# UART3 register map
Vendor: Texas Instruments
Peripheral module from a debugger description file (folder omap4460).
Registers are 32-bit, read-write, reset 0x0 unless marked. A register's access mark holds for its fields unless they carry their own. Offsets are as the file gives them; lines under a group give offsets from that group; [hi:lo] are bit positions; {n}, {i} and the like mark numbered series; 'fields as' and 'values as' point back to an identical list; <NAME> marks a mode.

## UART3
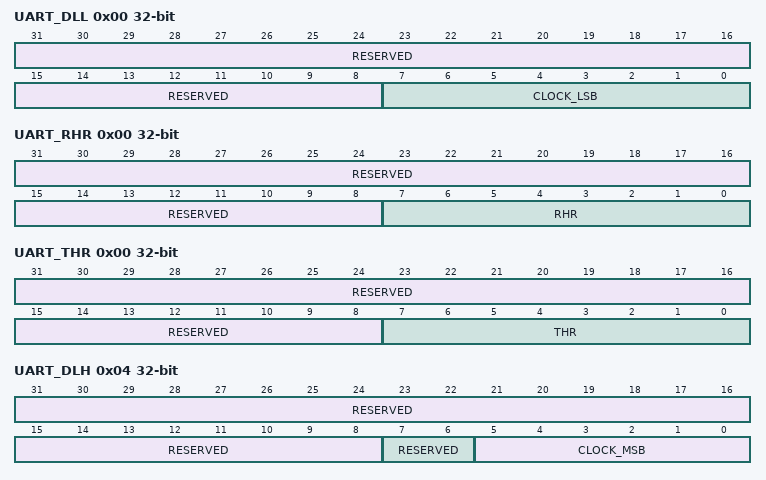
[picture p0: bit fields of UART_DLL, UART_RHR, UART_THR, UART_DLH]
0x00 UART_DLL — This register, with, stores the 14-bit divisor for generation of the baud clock in the baud rate generator. DLH stores the most-significant part of the divisor. DLL stores the least-significant part of the divisor.
  [31:8] RESERVED — Read returns 0. Write has no effect.
  [7:0] CLOCK_LSB — Stores the 8-bit LSB divisor value
0x00 UART_RHR ro (reset mask 0xFFFFFF00) — The receiver section consists of the receiver holding register (RHR) and the receiver shift register. The RHR is a 64-byte FIFO. The receiver shift register receives serial data from RX input. The data is converted to parallel data and moved to the RHR. If the FIFO is disabled, location 0 of the FIFO stores the single data character.Note:If an overflow occurs, the data in the RHR is not overwritten.
  [31:8] RESERVED — Read returns 0
  [7:0] RHR — Receive holding register
0x00 UART_THR wo (reset mask 0xFFFFFF00) — The transmitter section consists of the transmit holding register (THR) and the transmit shift register. The THR is a 64-byte FIFO. The local host (LH) writes data to the THR. The data is placed in the transmit shift register where it is shifted out serially on the TX output. If the FIFO is disabled, location 0 of the FIFO stores the data.
  [31:8] RESERVED — Write has no effect.
  [7:0] THR — Transmit holding register
0x04 UART_DLH — This register, with, stores the 14-bit divisor for generating the baud clock in the baud rate generator. DLH stores the most-significant part of the divisor. DLL stores the least-significant part of the divisor.
  [31:8] RESERVED — Read returns 0. Write has no effect.
  [7:6] RESERVED — Read returns 0. Write has no effect.
  [5:0] CLOCK_MSB — Stores the 6-bit MSB divisor value
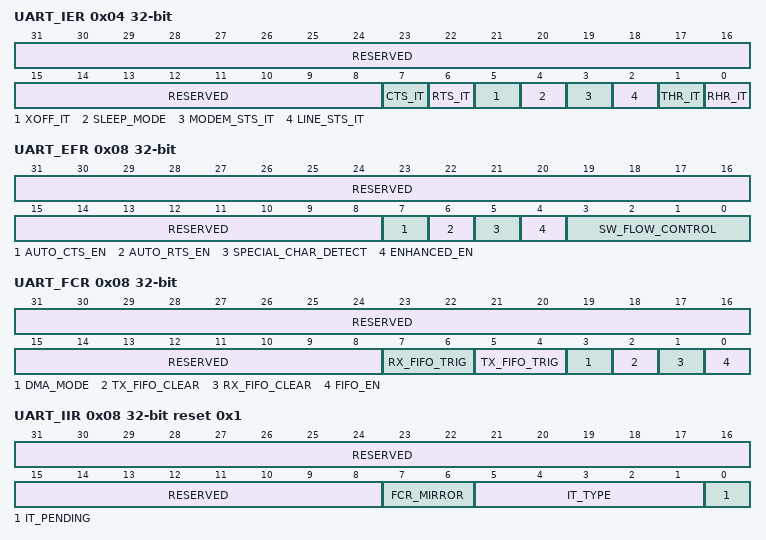
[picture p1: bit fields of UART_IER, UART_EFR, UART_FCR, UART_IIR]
0x04 UART_IER — Interrupt enable register
  [31:8] RESERVED — Read returns 0. Write has no effect.
  [7] CTS_IT
    0=Disables the CTS* interrupt; 1=Enables the CTS* interrupt
  [6] RTS_IT
    0=Disables the RTS* interrupt; 1=Enables the RTS* interrupt
  [5] XOFF_IT
    0=Disables the XOFF interrupt; 1=Enables the XOFF interrupt
  [4] SLEEP_MODE
    0=Disables sleep mode; 1=Enables sleep mode (stop baud rate clock when the module is inactive)
  [3] MODEM_STS_IT
    0=Disables the modem status register interrupt; 1=Enables the modem status register interrupt
  [2] LINE_STS_IT
    0=Disables the receiver line status interrupt; 1=Enables the receiver line status interrupt
  [1] THR_IT
    0=Disables the THR interrupt; 1=Enables the THR interrupt
  [0] RHR_IT
    0=Disables the RHR interrupt and time-out interrupt; 1=Enables the RHR interrupt and time-out interrupt
0x08 UART_EFR — Enhanced feature register
  [31:8] RESERVED — Read returns 0. Write has no effect.
  [7] AUTO_CTS_EN — Auto-CTS enable bit
    0=Normal operation; 1=Auto-CTS flow control is enabled. Transmission is halted when the CTS* pin is high (inactive).
  [6] AUTO_RTS_EN — Auto-RTS enable bit
    0=Normal operation; 1=Auto-RTS flow control is enabled. RTS* pin goes high (inactive) when the RX FIFO HALT trigger level,[3:0], is reached, and goes low (active) when the RX FIFO RESTORE transmission trigger level is reached.
  [5] SPECIAL_CHAR_DETECT
    0=Normal operation; 1=Special character detect enable. Received data is compared with XOFF2 data. If a match occurs, the received data is transferred to the RX FIFO and the[4] bit is set to 1 to indicate that a special character was detected.
  [4] ENHANCED_EN — Enhanced functions write enable bit
    0=Disables writing to IER bits 4-7, bits 4-5, and MCR bits 5-7; 1=Enables writing to IER bits 4-7, bits 4-5, and MCR bits 5-7
  [3:0] SW_FLOW_CONTROL — Combinations of software flow control can be selected by programming bit 3 - bit 0. See.
0x08 UART_FCR wo — FIFO control register
  [31:8] RESERVED — Write has no effect.
  [7:6] RX_FIFO_TRIG — Sets the trigger level for the RX FIFO: If UART_SCR[7] = 0 and UART_TLR[7:4] = 0000: 00: 8 characters 01: 16 characters 10: 56 characters 11: 60 characters If UART_SCR[7] = 0 and UART_TLR[7:4] != 0000, RX_FIFO_TRIG is not considered. If UART_SCR[7] = 1, RX_FIFO_TRIG is 2 LSBs of the trigger level (1-63 on 6 bits) with the granularity 1.
  [5:4] TX_FIFO_TRIG — Sets the trigger level for the TX FIFO: If UART_SCR[6] = 0 and UART_TLR[3:0] = 0000: 00: 8 spaces 01: 16 spaces 10: 32 spaces 11: 56 spaces If UART_SCR[6] = 0 and UART_TLR[3:0] != 0000, TX_FIFO_TRIG is not considered. If UART_SCR[6] = 1, TX_FIFO_TRIG is 2 LSBs of the trigger level (1-63 on 6 bits) with the granularity 1
  [3] DMA_MODE — This register is considered ifUART_SCR[0] = 0.
    0=DMA_MODE_0_w (DMA_MODE 0 (No DMA)); 1=DMA_MODE_1_w (DMA_MODE 1 (UART_nDMA_REQ[0] in TX, UART_nDMA_REQ[1] in RX))
  [2] TX_FIFO_CLEAR
    0=TX_FIFO_CLEAR_0_w (No change); 1=TX_FIFO_CLEAR_1_w (Clears the TX FIFO and resets its counter logic to 0. Returns to 0 after clearing FIFO.)
  [1] RX_FIFO_CLEAR
    0=RX_FIFO_CLEAR_0_w (No change); 1=RX_FIFO_CLEAR_1_w (Clears the RX FIFO and resets its counter logic to 0. Returns to 0 after clearing FIFO.)
  [0] FIFO_EN
    0=FIFO_EN_0_w (Disables the transmit and RX FIFOs. The transmit and receive holding registers are 1-byte FIFOs.); 1=FIFO_EN_1_w (Enables the transmit and RX FIFOs. The transmit and receive holding registers are 64-byte FIFOs.)
0x08 UART_IIR ro reset 0x1 — Interrupt identification register.
  [31:8] RESERVED — Read returns 0. Write has no effect.
  [7:6] FCR_MIRROR — Mirror the contents ofUART_FCR[0] on both bits.
  [5:1] IT_TYPE — Read 0x0: Modem interrupt. Priority = 4
    1=IT_TYPE_1_r (THR interrupt. Priority = 3); 2=IT_TYPE_2_r (RHR interrupt. Priority = 2); 3=IT_TYPE_3_r (Receiver line status error. Priority = 3); 6=IT_TYPE_6_r (Rx time-out. Priority = 2); 8=IT_TYPE_8_r (XOFF/special character. Priority = 5); 16=IT_TYPE_16_r (CTS, RTS, DSR change state from active (low) to inactive (high) Priority = 6)
  [0] IT_PENDING — Read 0x0: An interrupt is pending.
    1=IT_PENDING_1_r (No interrupt is pending.)
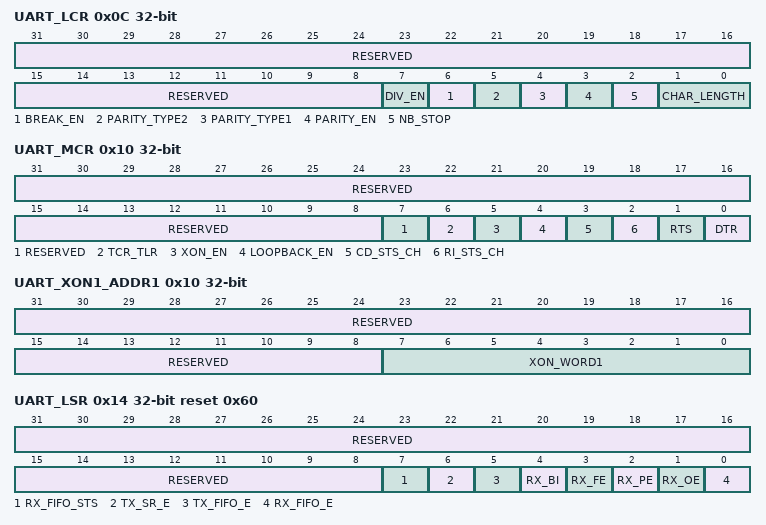
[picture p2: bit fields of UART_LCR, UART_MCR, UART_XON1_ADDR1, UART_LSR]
0x0C UART_LCR — Line control register
  [31:8] RESERVED — Read returns 0. Write has no effect.
  [7] DIV_EN
    0=Normal operating condition; 1=Divisor latch enable. Allows access to DLL, DLH, and other registers (see and ).
  [6] BREAK_EN — Break control bit
    0=Normal operating condition; 1=Forces the transmitter output to go low to alert the communication terminal
  [5] PARITY_TYPE2 — Selects the forced parity format (ifUART_LCR[3] = 1). If UART_LCR[5] = 1 and UART_LCR[4] = 0, the parity bit is forced to 1 in the transmitted and received data. If UART_LCR[5] = 1 and UART_LCR[4] = 1, the parity bit is forced to 0 in the transmitted and received data.
  [4] PARITY_TYPE1
    0=Odd parity is generated (if[3] = 1); 1=Even parity is generated (if[3] = 1)
  [3] PARITY_EN — 0x0: No parity
    1=A parity bit is generated during transmission and the receiver checks for received parity
  [2] NB_STOP — Specifies the number of stop-bits
    0=1 stop-bit (word length = 5, 6, 7, 8); 1=1.5 stop-bits (word length = 5) 2 stop-bits (word length = 6, 7, 8)
  [1:0] CHAR_LENGTH — Specifies the word length to be transmitted or received
    {v}={v+5} bits (v=0..3)
0x10 UART_MCR — Modem control register
  [31:8] RESERVED — Read returns 0. Write has no effect.
  [7] RESERVED — Read returns 0. Write has no effect.
  [6] TCR_TLR — 0x0: No action
    1=Enables access to the and registers
  [5] XON_EN — 0x0: Disable XON any function.
    1=Enable XON any function
  [4] LOOPBACK_EN — 0x0: Normal operating mode
    1=Enable local loopback mode (internal). In this mode, the MCR[3:0] signals are looped back into the[7:4] bit field. The transmit output is looped back to the receive input internally.
  [3] CD_STS_CH — 0x0: In loopback, forces DCD* input high and IRQ outputs to inactive state
    1=In loopback, forces DCD* input low and IRQ outputs to inactive state
  [2] RI_STS_CH — 0x0: In loopback, forces RI* input high
    1=In loopback, forces RI* input low
  [1] RTS — In loopback, controls theUART_MSR[4] bit. If auto-RTS is enabled, the RTS* output is controlled by hardware flow control.
    0=Force RTS* output to inactive (high); 1=Force RTS* output to active (low)
  [0] DTR — 0x0: Force DTR* output to inactive (high).
    1=Force DTR* output to active (low)
0x10 UART_XON1_ADDR1 — UART mode: XON1 character, IrDA mode: ADDR1 address
  [31:8] RESERVED — Read returns 0. Write has no effect.
  [7:0] XON_WORD1 — Stores the 8-bit XON1 character in UART modes and ADDR1 address 1 for IrDA modes
0x14 UART_LSR ro reset 0x60 — Line status register
  [31:8] RESERVED — Read returns 0.
  [7] RX_FIFO_STS — Read 0x0: Normal operation
    1=RX_FIFO_STS_1_r (At least one parity error, framing error, or break indication in the RX FIFO. Bit 7 is cleared when no more errors are present in the RX FIFO.)
  [6] TX_SR_E — Read 0x0: Transmitter hold (TX FIFO) and shift registers are not empty.
    1=TX_SR_E_1_r (Transmitter hold (TX FIFO) and shift registers are empty.)
  [5] TX_FIFO_E — Read 0x0: Transmit hold register (TX FIFO) is not empty.
    1=TX_FIFO_E_1_r (Transmit hold register (TX FIFO) is empty. The transmission is not necessarily complete.)
  [4] RX_BI — Read 0x0: No break condition
    1=RX_BI_1_r (A break was detected while the data from the RX FIFO was received (for example, RX input was low for one character + 1 bit time frame).)
  [3] RX_FE — Read 0x0: No framing error in data RX FIFO
    1=RX_FE_1_r (Framing error occurred in data from RX FIFO (received data did not have a valid stop-bit).)
  [2] RX_PE — Read 0x0: No parity error in data from RX FIFO
    1=RX_PE_1_r (Parity error in data from RX FIFO)
  [1] RX_OE — Read 0x0: No overrun error
    1=RX_OE_1_r (Overrun error occurred. Set when the character in the receive shift register is not transferred to the RX FIFO. This occurs only when the RX FIFO is full.)
  [0] RX_FIFO_E — Read 0x0: No data in the RX FIFO
    1=RX_FIFO_E_1_r (At least one data character in the RX FIFO)
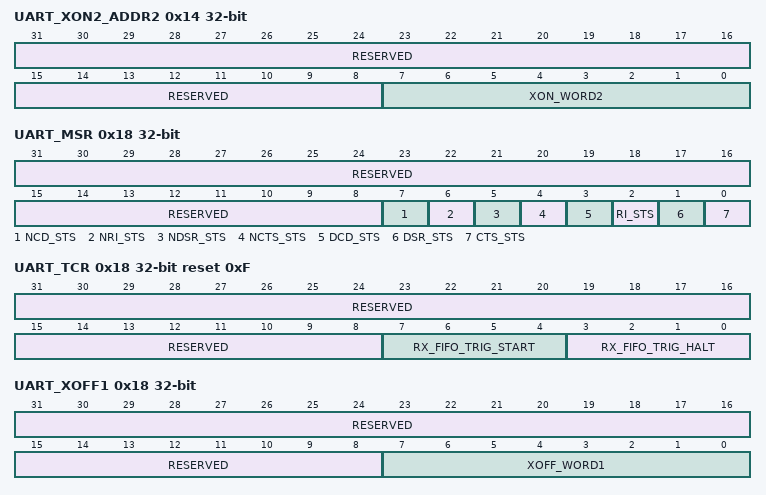
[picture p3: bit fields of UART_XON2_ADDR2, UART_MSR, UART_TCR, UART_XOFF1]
0x14 UART_XON2_ADDR2 — Stores the 8-bit XON2 character in UART moldes and ADDR2 address 2 for IrDA modes
  [31:8] RESERVED — Read returns 0. Write has no effect.
  [7:0] XON_WORD2 — Stores the 8-bit XON2 character in UART modes and ADDR2 address 2 for IrDA modes
0x18 UART_MSR ro (reset mask 0xFFFFFF0F) — Modem status register. UART mode only.
  [31:8] RESERVED — Read returns 0.
  [7] NCD_STS — This bit is the complement of the DCD* input. In loopback mode, it is equivalent toUART_MCR[3].
  [6] NRI_STS — This bit is the complement of the RI* input. In loopback mode, it is equivalent toUART_MCR[2].
  [5] NDSR_STS — This bit is the complement of the DSR* input. In loopback mode, it is equivalent toUART_MCR[0].
  [4] NCTS_STS — This bit is the complement of the CTS* input. In loopback mode, it is equivalent toUART_MCR[1].
  [3] DCD_STS — Indicates that DCD* input (orUART_MCR[3] in loopback) changed. Cleared on a read.
  [2] RI_STS — Indicates that RI* input (orUART_MCR[2] in loopback) changed state from low to high. Cleared on a read.
  [1] DSR_STS
    1=DSR_STS_1_r (Indicates that DSR* input (or[0] in loopback) changed state. Cleared on a read.)
  [0] CTS_STS
    1=CTS_STS_1_r (Indicates that CTS* input (or[1] in loopback) changed state. Cleared on a read.)
0x18 UART_TCR reset 0xF — Transmission control register
  [31:8] RESERVED — Read returns 0. Write has no effect.
  [7:4] RX_FIFO_TRIG_START — RX FIFO trigger level to RESTORE transmission (0 - 60)
  [3:0] RX_FIFO_TRIG_HALT — RX FIFO trigger level to HALT transmission (0 - 60)
0x18 UART_XOFF1 — UART mode XOFF1 character
  [31:8] RESERVED — Read returns 0. Write has no effect.
  [7:0] XOFF_WORD1 — Stores the 8-bit XOFF1 character used in UART modes
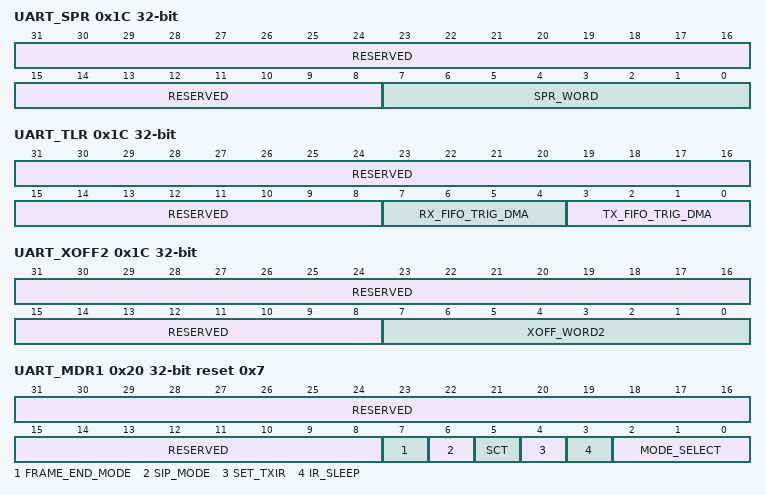
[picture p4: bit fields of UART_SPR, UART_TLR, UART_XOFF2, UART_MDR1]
0x1C UART_SPR — Scratchpad register
  [31:8] RESERVED — Read returns 0. Write has no effect.
  [7:0] SPR_WORD — Scratchpad register
0x1C UART_TLR — Trigger level register
  [31:8] RESERVED — Read returns 0. Write has no effect.
  [7:4] RX_FIFO_TRIG_DMA — Receive FIFO trigger level
  [3:0] TX_FIFO_TRIG_DMA — Transmit FIFO trigger level
0x1C UART_XOFF2 — UART mode XOFF2 character
  [31:8] RESERVED — Read returns 0. Write has no effect.
  [7:0] XOFF_WORD2 — Stores the 8-bit XOFF2 character used in UART modes.
0x20 UART_MDR1 reset 0x7 — Mode definition register 1
  [31:8] RESERVED — Read returns 0. Write has no effect.
  [7] FRAME_END_MODE — IrDA mode only
    0=Frame-length method; 1=Set EOT bit method
  [6] SIP_MODE — MIR/FIR modes only
    0=Manual SIP mode: SIP is generated with the control of ACREG[3]; 1=Automatic SIP mode: SIP is generated after each transmission
  [5] SCT — Store and control the transmission.
    0=Starts the infrared transmission when a value is written to THR; 1=Starts the infrared transmission with the control of ACREG[2]. Note: Before starting any transmission, there must be no reception ongoing.
  [4] SET_TXIR — Used to configure the infrared transceiver
    0=a) No action if MDR2[7] = 0 b) TXIR pin output is forced low if MDR2[7] = 1; 1=IRTX pin output is forced high (not dependent on MDR2[7] value)
  [3] IR_SLEEP — 0x0: IrDA/CIR sleep mode disabled
    1=IrDA/CIR sleep mode enabled
  [2:0] MODE_SELECT — 0x0: UART 16x mode
    1=SIR mode; 2=UART 16x auto-baud; 3=UART 13x mode; 4=MIR mode; 5=FIR mode; 6=CIR mode; 7=Disable (default state)
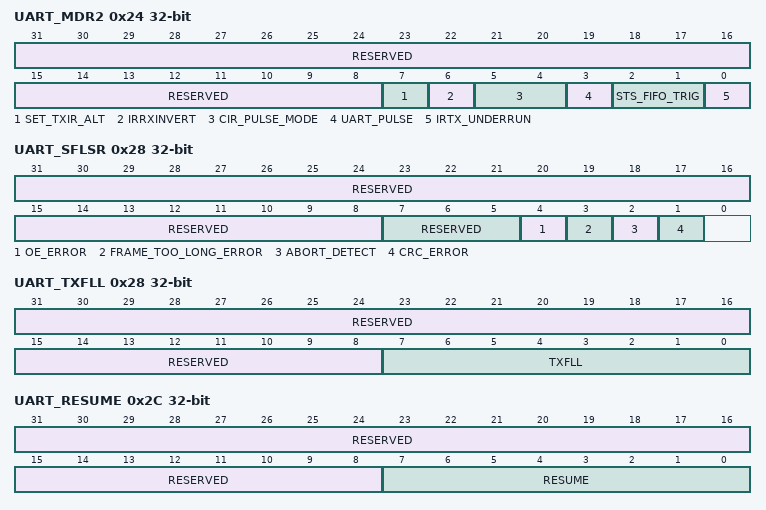
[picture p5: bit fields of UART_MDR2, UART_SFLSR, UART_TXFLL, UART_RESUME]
0x24 UART_MDR2 access per field — Mode definition register 2
  [31:8] RESERVED rw — Read returns 0. Write has no effect.
  [7] SET_TXIR_ALT ro — Provide alternate function for MDR1[4] (SET_TXIR).
    0=Normal mode; 1=Alternate mode for SET_TXIR
  [6] IRRXINVERT rw — IR mode only (IrDA and CIR). Invert RX pin in the module before the voting or sampling system logic of the infrared block. This does not affect the RX path in UART modem modes.
    0=Inversion is performed; 1=No inversion is performed
  [5:4] CIR_PULSE_MODE rw — CIR pulse modulation definition. Defines high level of the pulse width associated with a digit:
    {v}=Pulse width of {v+3} from 12 cycles (v=0..3)
  [3] UART_PULSE rw — UART mode only. Allows pulse shaping in UART mode.
    0=Normal UART mode; 1=UART mode with a pulse shaping
  [2:1] STS_FIFO_TRIG rw — IR-IrDA mode only. Frame status FIFO threshold select:
    0=1 entry; 1=4 entries; 2=7 entries; 3=8 entries
  [0] IRTX_UNDERRUN ro — IrDA transmission status interrupt. When theUART_IIR[5] interrupt occurs, the meaning of the interrupt is:
    0=IRTX_UNDERRUN_0_r (The last bit of the frame transmitted successfully without error.); 1=IRTX_UNDERRUN_1_r (An underrun occurred. The last bit of the frame was transmitted but with an underrun error. The bit is reset to 0 when the register is read.)
0x28 UART_SFLSR ro (reset mask 0xFFFFFFE1) — Status FIFO line status register
  [31:8] RESERVED — Read returns 0.
  [7:5] RESERVED — Read returns 0.
  [4] OE_ERROR — Read 0x1: Overrun error in RX FIFO when frame at top of RX FIFO was received Top of RX FIFO = Next frame to be read from RX FIFO
  [3] FRAME_TOO_LONG_ERROR — Read 0x1: Frame-length too long error in frame at top of RX FIFO
  [2] ABORT_DETECT — Read 0x1: Abort pattern detected in frame at top of RX FIFO
  [1] CRC_ERROR — Read 0x1: CRC error in frame at top of RX FIFO
0x28 UART_TXFLL wo — Transmit frame length register low
  [31:8] RESERVED — Write has no effect.
  [7:0] TXFLL — LSB register used to specify the frame length
0x2C UART_RESUME ro — IR-IrDA and IR-CIR modes only. This register is used to clear internal flags, which halt transmission/reception when an underrun/overrun error occurs. Reading this register resumes the halted operation. This register does not physically exist and reads always as 0x00.
  [31:8] RESERVED — Read returns 0.
  [7:0] RESUME — Dummy read to restart the TX or RX
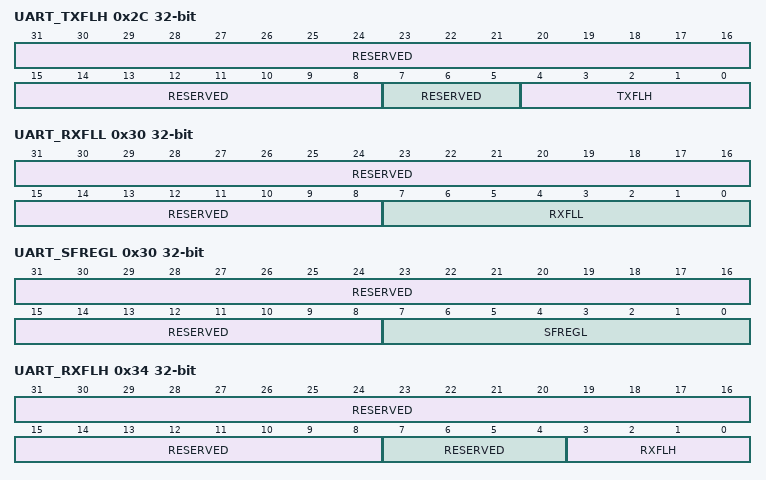
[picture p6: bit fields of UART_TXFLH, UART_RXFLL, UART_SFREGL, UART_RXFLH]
0x2C UART_TXFLH wo — Transmit frame length register high
  [31:8] RESERVED — Write has no effect.
  [7:5] RESERVED — Write has no effect.
  [4:0] TXFLH — MSB register used to specify the frame length
0x30 UART_RXFLL wo — Received frame length register low
  [31:8] RESERVED — Write has no effect.
  [7:0] RXFLL — LSB register used to specify the frame length in reception
0x30 UART_SFREGL ro (reset mask 0xFFFFFF00) — Status FIFO register low
  [31:8] RESERVED — Read returns 0.
  [7:0] SFREGL — LSB part of the frame length
0x34 UART_RXFLH wo — Received frame length register high
  [31:8] RESERVED — Write has no effect.
  [7:4] RESERVED — Write has no effect.
  [3:0] RXFLH — MSB register used to specify the frame length in reception
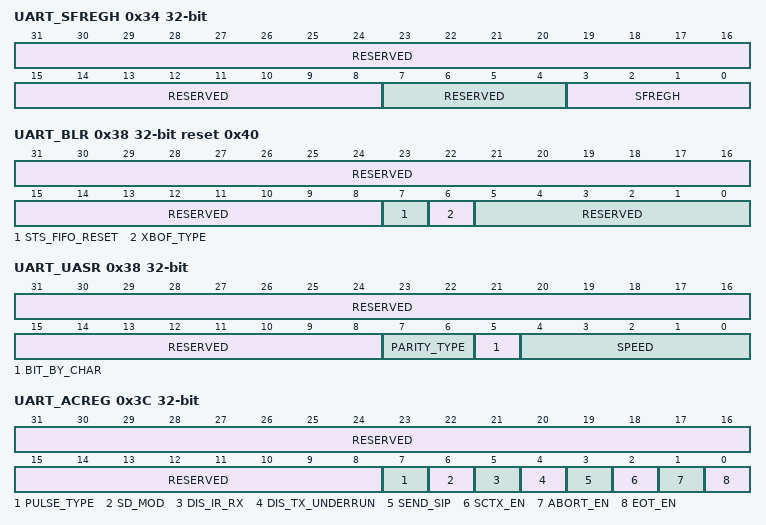
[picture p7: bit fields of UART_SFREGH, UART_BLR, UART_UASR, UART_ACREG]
0x34 UART_SFREGH ro (reset mask 0xFFFFFFF0) — Status FIFO register high
  [31:8] RESERVED — Read returns 0.
  [7:4] RESERVED — Read returns 0.
  [3:0] SFREGH — MSB part of the frame length
0x38 UART_BLR access per field reset 0x40 — BOF control register
  [31:8] RESERVED rw — Read returns 0. Write has no effect.
  [7] STS_FIFO_RESET rw — Status FIFO reset. This bit is self-clearing.
  [6] XBOF_TYPE rw — SIR xBOF select
    0=0xFF; 1=0xC0
  [5:0] RESERVED ro — Read returns 0.
0x38 UART_UASR ro — UART autobauding status register
  [31:8] RESERVED — Read returns 0.
  [7:6] PARITY_TYPE — Read 0x0: No parity identified
    1=PARITY_TYPE_1_r (Parity space); 2=PARITY_TYPE_2_r (Even parity); 3=PARITY_TYPE_3_r (Odd parity)
  [5] BIT_BY_CHAR — Read 0x0: 7-bit character identified
    1=BIT_BY_CHAR_1_r (8-bit character identified)
  [4:0] SPEED — Used to report the speed identified
    0=SPEED_0_r (No speed identified); 1=SPEED_1_r (115,200 baud); 2=SPEED_2_r (57,600 baud); 3=SPEED_3_r (38,400 baud); 4=SPEED_4_r (28,800 baud); 5=SPEED_5_r (19,200 baud); 6=SPEED_6_r (14,400 baud); 7=SPEED_7_r (9,600 baud); 8=SPEED_8_r (4,800 baud); 9=SPEED_9_r (2,400 baud); 10=SPEED_10_r (1,200 baud)
0x3C UART_ACREG — Auxiliary control register. IR-IrDA and IR-CIR modes only.
  [31:8] RESERVED — Read returns 0. Write has no effect.
  [7] PULSE_TYPE — SIR pulse width select
    0=3/16 of baud-rate pulse width; 1=1.6 µs
  [6] SD_MOD — Primary output used to configure transceivers. Connected to the SD/MODE input pin of IrDA transceivers.
    0=SD pin is set to high; 1=SD pin is set to low
  [5] DIS_IR_RX — 0x0: Normal operation (RX input automatically disabled during transmit but enabled outside of transmit operation)
    1=Disables RX input (permanent state - independent of transmit)
  [4] DIS_TX_UNDERRUN — It is recommended to disable TX FIFO underrun capability by masking corresponding underrun interrupt. When disabling underrun by setting ACREG[4] = 1, garbage data is sent over TX line.
    0=Long stop-bits cannot be transmitted; TX underrun is enabled; 1=Long stop-bits can be transmitted; TX underrun is disabled
  [3] SEND_SIP — MIR/FIR modes only. Send serial infrared interaction pulse (SIP). If this bit is set during an MIR/FIR transmission, the SIP is sent at the end of it. This bit is cleared automatically at the end of the SIP transmission.
    0=No action; 1=Send SIP pulse
  [2] SCTX_EN — Store and controlled TX start. When MDR1[5] = 1 and the LH writes 1 to this bit, the TX state-machine starts frame transmission. This bit is self-clearing.
  [1] ABORT_EN — Frame abort. The LH can intentionally abort transmission of a frame by writing 1 to this bit. Neither the end flag nor the CRC bits are appended to the frame. If TX FIFO is not empty and MDR1[5] = 1, UART IrDA starts a new transfer with data of the previous frame when the abort frame is sent. Therefore, TX FIFO must be reset before sending an abort frame.
  [0] EOT_EN — EOT (end of transmission) bit. The LH writes 1 to this bit just before it writes the last byte to the TX FIFO in set-EOT bit frame closing method. This bit is cleared automatically when the LH writes to the THR (TX FIFO).
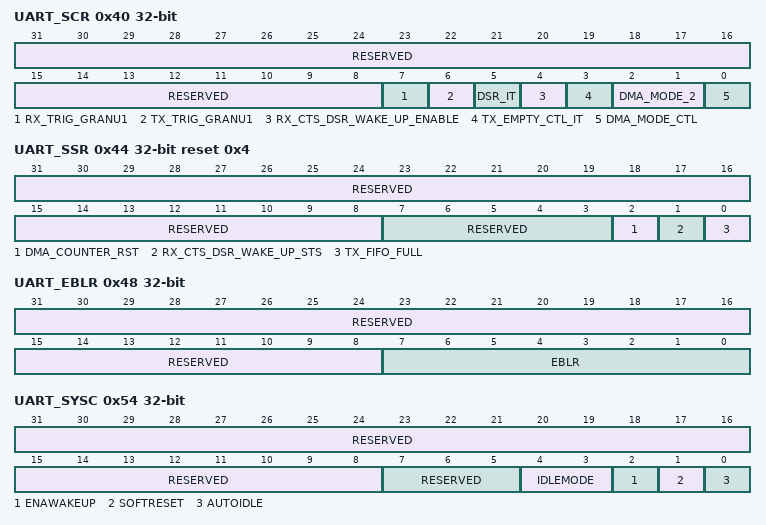
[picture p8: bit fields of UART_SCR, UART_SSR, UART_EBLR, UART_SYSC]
0x40 UART_SCR — Supplementary control register
  [31:8] RESERVED — Read returns 0. Write has no effect.
  [7] RX_TRIG_GRANU1 — 0x0: Disables the granularity of 1 for trigger RX level
    1=Enables the granularity of 1 for trigger RX level
  [6] TX_TRIG_GRANU1 — 0x0: Disables the granularity of 1 for trigger TX level
    1=Enables the granularity of 1 for trigger TX level
  [5] DSR_IT — 0x0: Disables DSR* interrupt
    1=Enables DSR* interrupt
  [4] RX_CTS_DSR_WAKE_UP_ENABLE — 0x0: Disables the wake-up interrupt and clears SSR[1]
    1=Waits for a falling edge of pins RX, CTS*, or DSR* to generate an interrupt
  [3] TX_EMPTY_CTL_IT — 0x0: Normal mode for THR interrupt (see UART mode interrupts table)
    1=The THR interrupt is generated when TX FIFO and TX shift register are empty
  [2:1] DMA_MODE_2 — Used to specify the DMA mode valid if theUART_SCR[0] bit = 1
    0=DMA mode 0 (no DMA); 1=DMA mode 1 (UART_nDMA_REQ[0] in TX, UART_nDMA_REQ[1] in RX); 2=DMA mode 2 (UART_nDMA_REQ[0] in RX); 3=DMA mode 3 (UART_nDMA_REQ[0] in TX)
  [0] DMA_MODE_CTL — 0x0: The DMA_MODE is set withUART_FCR[3].
    1=The DMA_MODE is set with[2:1]
0x44 UART_SSR access per field reset 0x4 — Supplementary status register
  [31:8] RESERVED ro — Read returns 0.
  [7:3] RESERVED ro — Read returns 0.
  [2] DMA_COUNTER_RST rw — 0x0: The DMA counter will not be reset if the corresponding FIFO is reset (through FCR[1] or FCR[2]).
    1=The DMA counter will be reset if corresponding FIFO is reset (through FCR[1] or FCR[2])
  [1] RX_CTS_DSR_WAKE_UP_STS ro — Read 0x0: No falling edge event on RX, CTS*, and DSR*
    1=RX_CTS_DSR_WAKE_UP_STS_1_r (A falling edge occurred on RX, CTS*, or DSR*.)
  [0] TX_FIFO_FULL ro — Read 0x0: TX FIFO is not full.
    1=TX_FIFO_FULL_1_r (TX FIFO is full.)
0x48 UART_EBLR — BOF length register
  [31:8] RESERVED — Read returns 0. Write has no effect.
  [7:0] EBLR — IR-IrDA mode: This register allows definition of up to 176 xBOFs, the maximum required by IrDA specification.
0x50 UART_MVR ro reset not defined — Module version register
  [31:0] REV — Revision number
0x54 UART_SYSC access per field — System configuration register
  [31:8] RESERVED rw — Read returns 0. Write has no effect.
  [7:5] RESERVED ro — Read returns 0.
  [4:3] IDLEMODE rw — Power management req/ack control ref: OCP Design Guidelines Version 1.1
    0=Force-idle: Idle request is acknowledged unconditionally; 1=No-idle: Idle request is never acknowledged; 2=Smart-idle: Idle request is acknowledged based in module internal activity; 3=Smart-idle Wake-up: Acknowledgement to an idle request is given based in the internal activity of the module. The module is allowed to generate wake-up request.
  [2] ENAWAKEUP rw — Wake-up feature control
    0=Wakeup is disabled; 1=Wake-up capability is enabled
  [1] SOFTRESET rw — Software reset. Set this bit to 1 to trigger a module reset. This bit is automatically reset by the hardware. Read returns 0.
    0=Normal mode; 1=The module is reset
  [0] AUTOIDLE rw — Internal OCP clock gating strategy
    0=Clock is running; 1=Automatic OCP clock gating strategy is applied, based on OCP interface activity
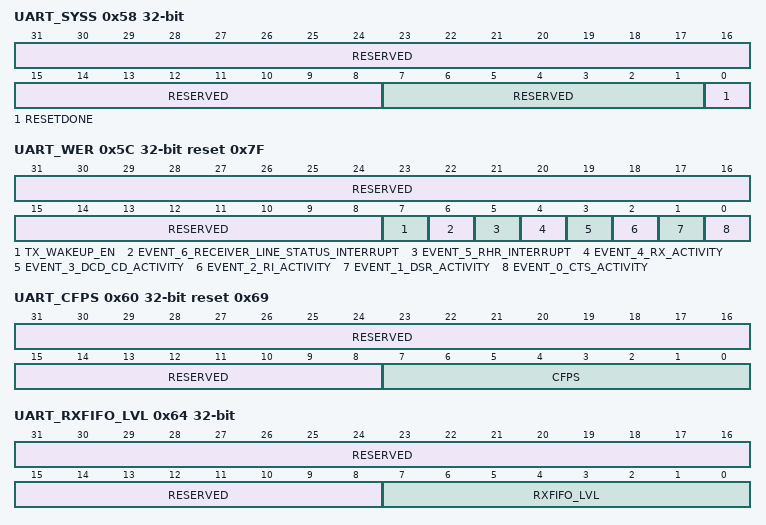
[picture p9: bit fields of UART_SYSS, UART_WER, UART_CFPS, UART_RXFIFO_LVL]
0x58 UART_SYSS ro — System status register
  [31:8] RESERVED — Read returns 0.
  [7:1] RESERVED — Read returns 0.
  [0] RESETDONE — Internal reset monitoring
    0=RESETDONE_0_r (Internal module reset is ongoing.); 1=RESETDONE_1_r (Reset complete)
0x5C UART_WER reset 0x7F — Wake-up enable register
  [31:8] RESERVED — Read returns 0. Write has no effect.
  [7] TX_WAKEUP_EN — 0x0: Event is not allowed to wake up the system.
    1=Event can wake up the system: it can be THR_IT or TX_DMA request and/or TX_SATUS_IT
  [6] EVENT_6_RECEIVER_LINE_STATUS_INTERRUPT — 0x0: Event is not allowed to wake up the system.
    1=Event can wake up the system
  [5] EVENT_5_RHR_INTERRUPT — 0x0: Event is not allowed to wake up the system.
    1=Event can wake up the system
  [4] EVENT_4_RX_ACTIVITY — 0x0: Event is not allowed to wake up the system.
    1=Event can wake up the system
  [3] EVENT_3_DCD_CD_ACTIVITY — 0x0: Event is not allowed to wake up the system
    1=Event can wake up the system
  [2] EVENT_2_RI_ACTIVITY — 0x0: Event is not allowed to wake up the system.
    1=Event can wake up the system
  [1] EVENT_1_DSR_ACTIVITY — 0x0: Event is not allowed to wake up the system.
    1=Event can wake up the system
  [0] EVENT_0_CTS_ACTIVITY — 0x0: Event is not allowed to wake up the system.
    1=Event can wake up the system
0x60 UART_CFPS reset 0x69 — Carrier frequency prescaler
  [31:8] RESERVED — Read returns 0. Write has no effect.
  [7:0] CFPS — System clock frequency prescaler at (12x multiple). Examples for CFPS values:Target Freq (kHz) CFPS (decimal) Actual Freq (kHz) . 30 133 30.08 . 32.75 122 32.79 . 36 111 36.04 . 36.7 109 36.69 . 38* 105 38.1 . 40 100 40 . 56.8 70 57.14 . *configured at reset to this value . Note:CFPS = 0 is not supported. .
0x64 UART_RXFIFO_LVL ro — Level of the RX FIFO
  [31:8] RESERVED — Read returns 0.
  [7:0] RXFIFO_LVL — Shows the number of received bytes in the RX FIFO
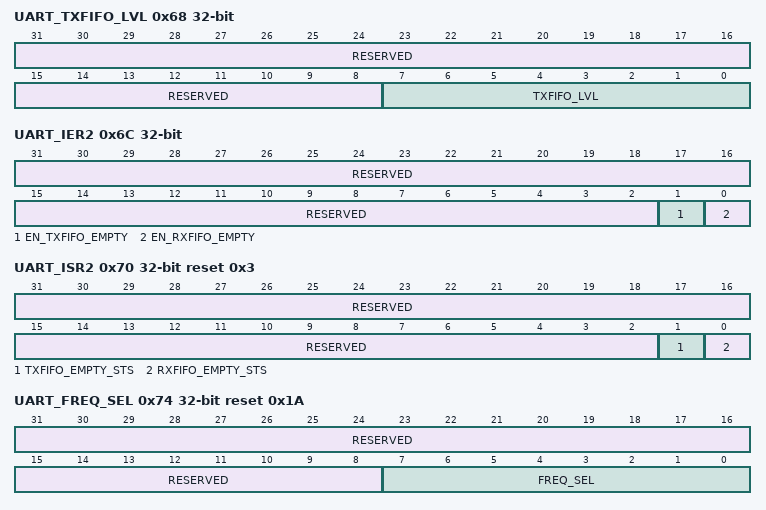
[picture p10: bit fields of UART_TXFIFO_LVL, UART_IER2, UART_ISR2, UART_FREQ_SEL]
0x68 UART_TXFIFO_LVL ro — Level of the TX FIFO
  [31:8] RESERVED — Read returns 0.
  [7:0] TXFIFO_LVL — Shows the number of written bytes in the TX FIFO
0x6C UART_IER2 — Enables RX/TX FIFOs empty corresponding interrupts
  [31:2] RESERVED — Read returns 0. Write has no effect.
  [1] EN_TXFIFO_EMPTY — Enables TX FIFO empty corresponding interrupt
    0=Enables EN_TXFIFO_EMPTY interrupt; 1=Disables EN_TXFIFO_EMPTY interrupt
  [0] EN_RXFIFO_EMPTY — Enables RX FIFO empty corresponding interrupt
    0=Enables EN_RXFIFO_EMPTY interrupt; 1=Disables EN_RXFIFO_EMPTY interrupt
0x70 UART_ISR2 reset 0x3 — Status of RX/TX FIFOs empty corresponding interrupts
  [31:2] RESERVED — Read returns 0. Write has no effect.
  [1] TXFIFO_EMPTY_STS — Used to generate interrupt if the TX_FIFO is empty (software flow control)
    0=TXFIFO_EMPTY interrupt not pending; 1=TXFIFO_EMPTY interrupt pending
  [0] RXFIFO_EMPTY_STS — Used to generate interrupt if the RX_FIFO is empty (software flow control)
    0=RXFIFO_EMPTY interrupt not pending; 1=RXFIFO_EMPTY interrupt pending
0x74 UART_FREQ_SEL reset 0x1A — Sample per bit selector
  [31:8] RESERVED — Read returns 0. Write has no effect.
  [7:0] FREQ_SEL — Sets the sample per bit if nondefault frequency is used. MDR3[1] must be set to 1 after this value is set. Must be equal to or higher then 6.
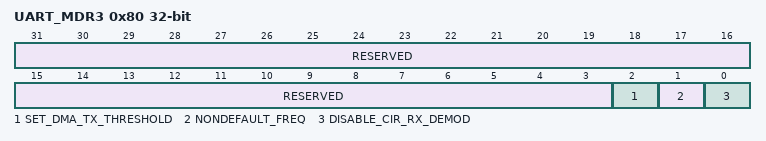
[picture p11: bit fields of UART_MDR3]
0x80 UART_MDR3 — Mode definition register 3
  [31:3] RESERVED — Read returns 0. Write has no effect.
  [2] SET_DMA_TX_THRESHOLD — Enable to set different TXDMA threshold inUART_TX_DMA_THRESHOLD register.
  [1] NONDEFAULT_FREQ — Used to enable the NONDEFAULT fclk frequencies.
    0=Disables using NONDEFAULT fclk frequencies; 1=Enables using NONDEFAULT fclk frequencies (set FREQ_SEL and DLH/DLL)
  [0] DISABLE_CIR_RX_DEMOD — Used to enable CIR RX demodulation.
    0=Enables CIR RX demodulation; 1=Disables CIR RX demodulation
0x84 UART_TX_DMA_THRESHOLD — Use to manually set the TX DMA threshold level. [2] SET_TX_DMA_THRESHOLD must be 1 and must be value + tx_trigger_level = 64 (TX FIFO size). If not, 64-tx_trigger_level will be used without modifying the value of this register.
  [5:0] TX_DMA_THRESHOLD — Used to manually set the TX DMA threshold level
